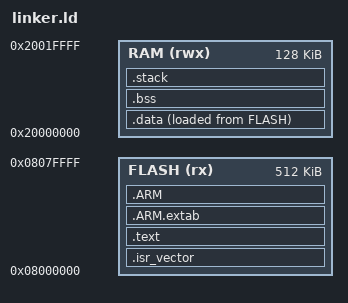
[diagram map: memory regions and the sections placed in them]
/*
 * hart-bleeder — linker.ld
 * Linker script for STM32G474CEU6 (512 KB flash, 128 KB SRAM).
 *
 * Author: jayis1
 * License: GPL-2.0
 */

ENTRY(Reset_Handler)

MEMORY
{
    FLASH (rx)  : ORIGIN = 0x08000000, LENGTH = 512K
    RAM   (rwx) : ORIGIN = 0x20000000, LENGTH = 128K
}

_estack = ORIGIN(RAM) + LENGTH(RAM);

SECTIONS
{
    .isr_vector :
    {
        . = ALIGN(4);
        KEEP(*(.isr_vector))
        . = ALIGN(4);
    } > FLASH

    .text :
    {
        . = ALIGN(4);
        *(.text)
        *(.text*)
        *(.rodata)
        *(.rodata*)
        . = ALIGN(4);
        _etext = .;
    } > FLASH

    .ARM.extab :
    {
        *(.ARM.extab* .gnu.linkonce.armextab.*)
    } > FLASH

    .ARM :
    {
        __exidx_start = .;
        *(.ARM.exidx*)
        __exidx_end = .;
    } > FLASH

    .data :
    {
        . = ALIGN(4);
        _sdata = .;
        *(.data)
        *(.data*)
        . = ALIGN(4);
        _edata = .;
    } > RAM AT > FLASH
    _sidata = LOADADDR(.data);

    .bss (NOLOAD) :
    {
        . = ALIGN(4);
        _sbss = .;
        *(.bss)
        *(.bss*)
        *(COMMON)
        . = ALIGN(4);
        _ebss = .;
    } > RAM

    .stack (NOLOAD) :
    {
        . = ALIGN(8);
        . = . + 0x1000;
        . = ALIGN(8);
    } > RAM

    _heap_start = .;
    _heap_end = ORIGIN(RAM) + LENGTH(RAM) - 0x1000;
}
